AUTOSAR XML (schema 3.1.2)
package /Components/SWC_EOMGsl
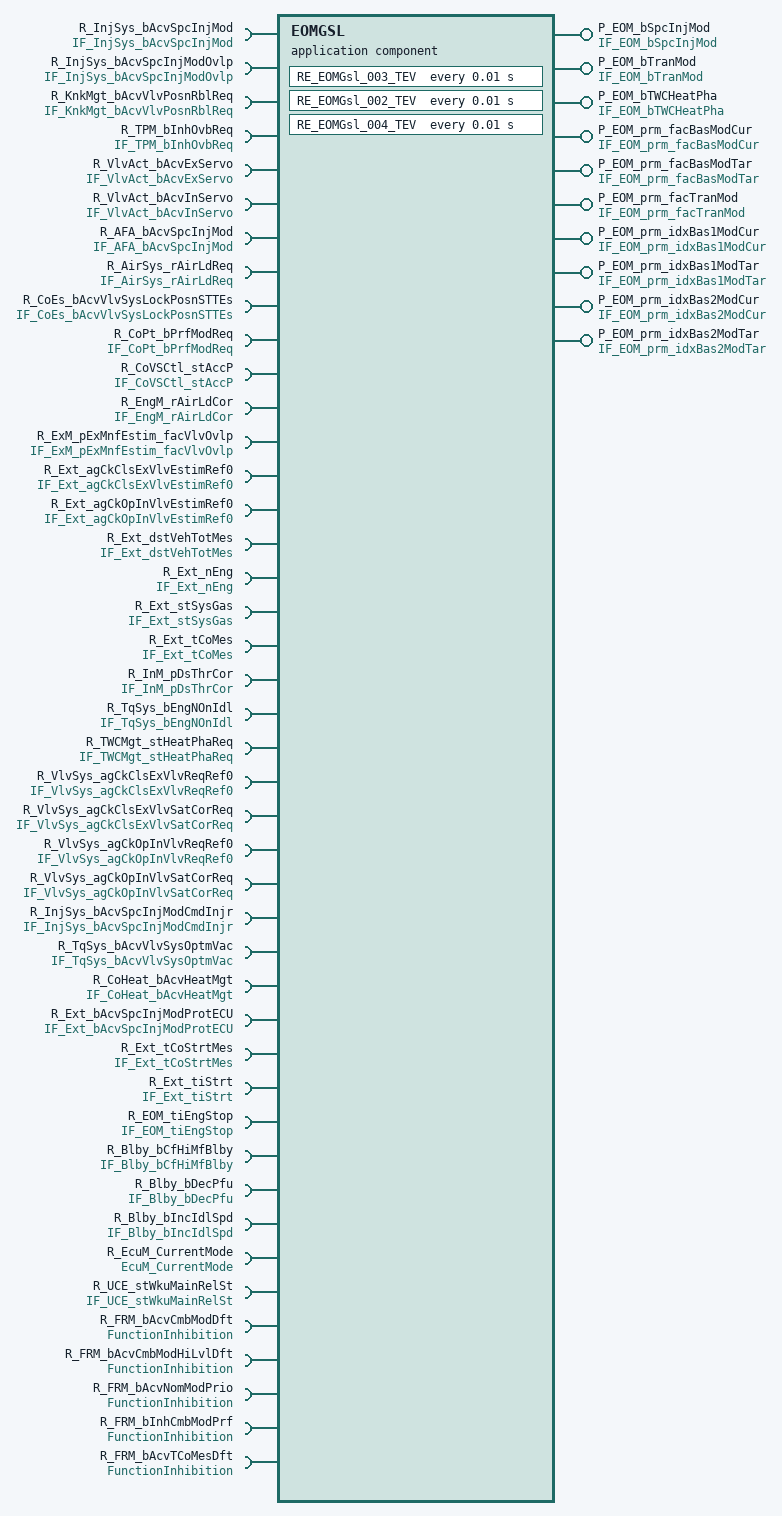
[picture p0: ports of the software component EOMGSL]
  application software component type EOMGSL
    43 x require port:
      R_InjSys_bAcvSpcInjMod: unqueued-receiver-com-spec{data-element=InjSys_bAcvSpcInjMod, init-value=ConstantValue, resync-time=0}, required-interface=IF_InjSys_bAcvSpcInjMod  # Receiver of interface IF_InjSys_bAcvSpcInjMod - Requirement Reference: [01552_10_03637-EOMGsl.I004(0)]
      R_InjSys_bAcvSpcInjModOvlp: unqueued-receiver-com-spec{data-element=InjSys_bAcvSpcInjModOvlp, init-value=ConstantValue1, resync-time=0}, required-interface=IF_InjSys_bAcvSpcInjModOvlp  # Receiver of interface IF_InjSys_bAcvSpcInjModOvlp - Requirement Reference: [01552_10_03637-EOMGsl.I005(0)]
      R_KnkMgt_bAcvVlvPosnRblReq: unqueued-receiver-com-spec{data-element=KnkMgt_bAcvVlvPosnRblReq, init-value=ConstantValue3, resync-time=0}, required-interface=IF_KnkMgt_bAcvVlvPosnRblReq  # Receiver of interface IF_KnkMgt_bAcvVlvPosnRblReq - Requirement Reference: [01552_10_03637-EOMGsl.I006(0)]
      R_TPM_bInhOvbReq: unqueued-receiver-com-spec{data-element=TPM_bInhOvbReq, init-value=ConstantValue5, resync-time=0}, required-interface=IF_TPM_bInhOvbReq  # Receiver of interface IF_TPM_bInhOvbReq - Requirement Reference: [01552_10_03637-EOMGsl.I007(0)]
      R_VlvAct_bAcvExServo: unqueued-receiver-com-spec{data-element=VlvAct_bAcvExServo, init-value=ConstantValue7, resync-time=0}, required-interface=IF_VlvAct_bAcvExServo  # Receiver of interface IF_VlvAct_bAcvExServo - Requirement Reference: [01552_10_03637-EOMGsl.I008(0)]
      R_VlvAct_bAcvInServo: unqueued-receiver-com-spec{data-element=VlvAct_bAcvInServo, init-value=ConstantValue9, resync-time=0}, required-interface=IF_VlvAct_bAcvInServo  # Receiver of interface IF_VlvAct_bAcvInServo - Requirement Reference: [01552_10_03637-EOMGsl.I009(1)]
      R_AFA_bAcvSpcInjMod: unqueued-receiver-com-spec{data-element=AFA_bAcvSpcInjMod, init-value=ConstantValue11, resync-time=0}, required-interface=IF_AFA_bAcvSpcInjMod  # Receiver of interface IF_AFA_bAcvSpcInjMod - Requirement Reference: [01552_10_03637-EOMGsl.I010(0)]
      R_AirSys_rAirLdReq: unqueued-receiver-com-spec{data-element=AirSys_rAirLdReq, init-value=ConstantValue13, resync-time=0}, required-interface=IF_AirSys_rAirLdReq  # Receiver of interface IF_AirSys_rAirLdReq - Requirement Reference: [01552_10_03637-EOMGsl.I011(1)]
      R_CoEs_bAcvVlvSysLockPosnSTTEs: unqueued-receiver-com-spec{data-element=CoEs_bAcvVlvSysLockPosnSTTEs, init-value=ConstantValue15, resync-time=0}, required-interface=IF_CoEs_bAcvVlvSysLockPosnSTTEs  # Receiver of interface IF_CoEs_bAcvVlvSysLockPosnSTTEs - Requirement Reference: [01552_10_03637-EOMGsl.I012(0)]
      R_CoPt_bPrfModReq: unqueued-receiver-com-spec{data-element=CoPt_bPrfModReq, init-value=ConstantValue17, resync-time=0}, required-interface=IF_CoPt_bPrfModReq  # Receiver of interface IF_CoPt_bPrfModReq - Requirement Reference: [01552_10_03637-EOMGsl.I013(1)]
      R_CoVSCtl_stAccP: unqueued-receiver-com-spec{data-element=CoVSCtl_stAccP, init-value=ConstantValue19, resync-time=0}, required-interface=IF_CoVSCtl_stAccP  # Receiver of interface IF_CoVSCtl_stAccP - Requirement Reference: [01552_10_03637-EOMGsl.I014(0)]
      R_EngM_rAirLdCor: unqueued-receiver-com-spec{data-element=EngM_rAirLdCor, init-value=ConstantValue21, resync-time=0}, required-interface=IF_EngM_rAirLdCor  # Receiver of interface IF_EngM_rAirLdCor - Requirement Reference: [01552_10_03637-EOMGsl.I015(1)]
      R_ExM_pExMnfEstim_facVlvOvlp: unqueued-receiver-com-spec{data-element=ExM_pExMnfEstim_facVlvOvlp, init-value=ConstantValue23, resync-time=0}, required-interface=IF_ExM_pExMnfEstim_facVlvOvlp  # Receiver of interface IF_ExM_pExMnfEstim_facVlvOvlp - Requirement Reference: [01552_10_03637-EOMGsl.I019(0)]
      R_Ext_agCkClsExVlvEstimRef0: unqueued-receiver-com-spec{data-element=Ext_agCkClsExVlvEstimRef0, init-value=ConstantValue25, resync-time=0}, required-interface=IF_Ext_agCkClsExVlvEstimRef0  # Receiver of interface IF_Ext_agCkClsExVlvEstimRef0 - Requirement Reference: [01552_10_03637-EOMGsl.I020(1)]
      R_Ext_agCkOpInVlvEstimRef0: unqueued-receiver-com-spec{data-element=Ext_agCkOpInVlvEstimRef0, init-value=ConstantValue27, resync-time=0}, required-interface=IF_Ext_agCkOpInVlvEstimRef0  # Receiver of interface IF_Ext_agCkOpInVlvEstimRef0 - Requirement Reference: [01552_10_03637-EOMGsl.I021(1)]
      R_Ext_dstVehTotMes: unqueued-receiver-com-spec{data-element=Ext_dstVehTotMes, init-value=ConstantValue29, resync-time=0}, required-interface=IF_Ext_dstVehTotMes  # Receiver of interface IF_Ext_dstVehTotMes - Requirement Reference: [01552_10_03637-EOMGsl.I022(0)]
      R_Ext_nEng: unqueued-receiver-com-spec{data-element=Ext_nEng, init-value=ConstantValue31, resync-time=0}, required-interface=IF_Ext_nEng  # Receiver of interface IF_Ext_nEng - Requirement Reference: [01552_10_03637-EOMGsl.I023(0)]
      R_Ext_stSysGas: unqueued-receiver-com-spec{data-element=Ext_stSysGas, init-value=ConstantValue33, resync-time=0}, required-interface=IF_Ext_stSysGas  # Receiver of interface IF_Ext_stSysGas - Requirement Reference: [01552_10_03637-EOMGsl.I024(1)]
      R_Ext_tCoMes: unqueued-receiver-com-spec{data-element=Ext_tCoMes, init-value=ConstantValue35, resync-time=0}, required-interface=IF_Ext_tCoMes  # Receiver of interface IF_Ext_tCoMes - Requirement Reference: [01552_10_03637-EOMGsl.I025(0)]
      R_InM_pDsThrCor: unqueued-receiver-com-spec{data-element=InM_pDsThrCor, init-value=ConstantValue37, resync-time=0}, required-interface=IF_InM_pDsThrCor  # Receiver of interface IF_InM_pDsThrCor - Requirement Reference: [01552_10_03637-EOMGsl.I026(0)]
      R_TqSys_bEngNOnIdl: unqueued-receiver-com-spec{data-element=TqSys_bEngNOnIdl, init-value=ConstantValue39, resync-time=0}, required-interface=IF_TqSys_bEngNOnIdl  # Receiver of interface IF_TqSys_bEngNOnIdl - Requirement Reference: [01552_10_03637-EOMGsl.I027(0)]
      R_TWCMgt_stHeatPhaReq: unqueued-receiver-com-spec{data-element=TWCMgt_stHeatPhaReq, init-value=ConstantValue41, resync-time=0}, required-interface=IF_TWCMgt_stHeatPhaReq  # Receiver of interface IF_TWCMgt_stHeatPhaReq - Requirement Reference: [01552_10_03637-EOMGsl.I028(0)]
      R_VlvSys_agCkClsExVlvReqRef0: unqueued-receiver-com-spec{data-element=VlvSys_agCkClsExVlvReqRef0, init-value=ConstantValue43, resync-time=0}, required-interface=IF_VlvSys_agCkClsExVlvReqRef0  # Receiver of interface IF_VlvSys_agCkClsExVlvReqRef0 - Requirement Reference: [01552_10_03637-EOMGsl.I029(2)]
      R_VlvSys_agCkClsExVlvSatCorReq: unqueued-receiver-com-spec{data-element=VlvSys_agCkClsExVlvSatCorReq, init-value=ConstantValue45, resync-time=0}, required-interface=IF_VlvSys_agCkClsExVlvSatCorReq  # Receiver of interface IF_VlvSys_agCkClsExVlvSatCorReq - Requirement Reference: [01552_10_03637-EOMGsl.I030(1)]
      R_VlvSys_agCkOpInVlvReqRef0: unqueued-receiver-com-spec{data-element=VlvSys_agCkOpInVlvReqRef0, init-value=ConstantValue47, resync-time=0}, required-interface=IF_VlvSys_agCkOpInVlvReqRef0  # Receiver of interface IF_VlvSys_agCkOpInVlvReqRef0 - Requirement Reference: [01552_10_03637-EOMGsl.I031(2)]
      R_VlvSys_agCkOpInVlvSatCorReq: unqueued-receiver-com-spec{data-element=VlvSys_agCkOpInVlvSatCorReq, init-value=ConstantValue49, resync-time=0}, required-interface=IF_VlvSys_agCkOpInVlvSatCorReq  # Receiver of interface IF_VlvSys_agCkOpInVlvSatCorReq - Requirement Reference: [01552_10_03637-EOMGsl.I032(1)]
      R_InjSys_bAcvSpcInjModCmdInjr: unqueued-receiver-com-spec{data-element=InjSys_bAcvSpcInjModCmdInjr, init-value=ConstantValue51, resync-time=0}, required-interface=IF_InjSys_bAcvSpcInjModCmdInjr  # Receiver of interface IF_InjSys_bAcvSpcInjModCmdInjr - Requirement Reference: [01552_10_03637-EOMGsl.I065(0)]
      R_TqSys_bAcvVlvSysOptmVac: unqueued-receiver-com-spec{data-element=TqSys_bAcvVlvSysOptmVac, init-value=ConstantValue53, resync-time=0}, required-interface=IF_TqSys_bAcvVlvSysOptmVac  # Receiver of interface IF_TqSys_bAcvVlvSysOptmVac - Requirement Reference: [01552_10_03637-EOMGsl.I088(0)]
      R_CoHeat_bAcvHeatMgt: unqueued-receiver-com-spec{data-element=CoHeat_bAcvHeatMgt, init-value=ConstantValue55, resync-time=0}, required-interface=IF_CoHeat_bAcvHeatMgt  # Receiver of interface IF_CoHeat_bAcvHeatMgt - Requirement Reference: [01552_10_03637-EOMGsl.I091(0)]
      R_Ext_bAcvSpcInjModProtECU: unqueued-receiver-com-spec{data-element=Ext_bAcvSpcInjModProtECU, init-value=ConstantValue57, resync-time=0}, required-interface=IF_Ext_bAcvSpcInjModProtECU  # Receiver of interface IF_Ext_bAcvSpcInjModProtECU - Requirement Reference: [01552_10_03637-EOMGsl.I092(0)]
      R_Ext_tCoStrtMes: unqueued-receiver-com-spec{data-element=Ext_tCoStrtMes, init-value=ConstantValue59, resync-time=0}, required-interface=IF_Ext_tCoStrtMes  # Receiver of interface IF_Ext_tCoStrtMes - Requirement Reference: [01552_10_03637-EOMGsl.I093(0)]
      R_Ext_tiStrt: unqueued-receiver-com-spec{data-element=Ext_tiStrt, init-value=ConstantValue61, resync-time=0}, required-interface=IF_Ext_tiStrt  # Receiver of interface IF_Ext_tiStrt - Requirement Reference: [01552_10_03637-EOMGsl-I094(0)]
      R_EOM_tiEngStop: unqueued-receiver-com-spec{data-element=EOM_tiEngStop, init-value=ConstantValue63, resync-time=0}, required-interface=IF_EOM_tiEngStop  # Receiver of interface IF_EOM_tiEngStop - Requirement Reference: [01552_10_03637-EOMGsl-I095(0)]
      R_Blby_bCfHiMfBlby: unqueued-receiver-com-spec{data-element=Blby_bCfHiMfBlby, init-value=ConstantValue65, resync-time=0}, required-interface=IF_Blby_bCfHiMfBlby  # Receiver of interface IF_Blby_bCfHiMfBlby - Requirement Reference: [01552_10_03637-EOMGsl-I096(0)]
      R_Blby_bDecPfu: unqueued-receiver-com-spec{data-element=Blby_bDecPfu, init-value=ConstantValue67, resync-time=0}, required-interface=IF_Blby_bDecPfu  # Receiver of interface IF_Blby_bDecPfu - Requirement Reference: [01552_10_03637-EOMGsl-I097(0)]
      R_Blby_bIncIdlSpd: unqueued-receiver-com-spec{data-element=Blby_bIncIdlSpd, init-value=ConstantValue69, resync-time=0}, required-interface=IF_Blby_bIncIdlSpd  # Receiver of interface IF_Blby_bIncIdlSpd - Requirement Reference: [01552_10_03637-EOMGsl-I098(0)]
      R_EcuM_CurrentMode: required-interface=EcuM_CurrentMode
      R_UCE_stWkuMainRelSt: required-interface=IF_UCE_stWkuMainRelSt
      R_FRM_bAcvCmbModDft: required-interface=FunctionInhibition  # 01552_10_03637-EOMGsl.I060(0)
      R_FRM_bAcvCmbModHiLvlDft: required-interface=FunctionInhibition  # 01552_10_03637-EOMGsl.I061(0)
      R_FRM_bAcvNomModPrio: required-interface=FunctionInhibition  # 01552_10_03637-EOMGsl.I062(0)
      R_FRM_bInhCmbModPrf: required-interface=FunctionInhibition  # 01552_10_03637-EOMGsl.I063(0)
      R_FRM_bAcvTCoMesDft: required-interface=FunctionInhibition  # 01552_10_03637-EOMGsl.I064(0)
    10 x provide port:
      P_EOM_bSpcInjMod: unqueued-sender-com-spec{data-element=EOM_bSpcInjMod, can-invalidate=false, init-value=ConstantValue71}, provided-interface=IF_EOM_bSpcInjMod
      P_EOM_bTranMod: unqueued-sender-com-spec{data-element=EOM_bTranMod, can-invalidate=false, init-value=ConstantValue73}, provided-interface=IF_EOM_bTranMod
      P_EOM_bTWCHeatPha: unqueued-sender-com-spec{data-element=EOM_bTWCHeatPha, can-invalidate=false, init-value=ConstantValue75}, provided-interface=IF_EOM_bTWCHeatPha
      P_EOM_prm_facBasModCur: unqueued-sender-com-spec{data-element=EOM_prm_facBasModCur, can-invalidate=false, init-value=EOM_prm_facBasModCur_Cst}, provided-interface=IF_EOM_prm_facBasModCur
      P_EOM_prm_facBasModTar: unqueued-sender-com-spec{data-element=EOM_prm_facBasModTar, can-invalidate=false, init-value=EOM_prm_facBasModTar_Cst}, provided-interface=IF_EOM_prm_facBasModTar
      P_EOM_prm_facTranMod: unqueued-sender-com-spec{data-element=EOM_prm_facTranMod, can-invalidate=false, init-value=EOM_prm_facTranMod_Cst}, provided-interface=IF_EOM_prm_facTranMod
      P_EOM_prm_idxBas1ModCur: unqueued-sender-com-spec{data-element=EOM_prm_idxBas1ModCur, can-invalidate=false, init-value=EOM_prm_idxBas1ModCur_Cst}, provided-interface=IF_EOM_prm_idxBas1ModCur
      P_EOM_prm_idxBas1ModTar: unqueued-sender-com-spec{data-element=EOM_prm_idxBas1ModTar, can-invalidate=false, init-value=EOM_prm_idxBas1ModTar_Cst}, provided-interface=IF_EOM_prm_idxBas1ModTar
      P_EOM_prm_idxBas2ModCur: unqueued-sender-com-spec{data-element=EOM_prm_idxBas2ModCur, can-invalidate=false, init-value=EOM_prm_idxBas2ModCur_Cst}, provided-interface=IF_EOM_prm_idxBas2ModCur
      P_EOM_prm_idxBas2ModTar: unqueued-sender-com-spec{data-element=EOM_prm_idxBas2ModTar, can-invalidate=false, init-value=EOM_prm_idxBas2ModTar_Cst}, provided-interface=IF_EOM_prm_idxBas2ModTar
  68 x constant specification:
    ConstantValue
      value:
        boolean literal ConstantValue: type=DT_InjSys_bAcvSpcInjMod, value=false
    ConstantValue1
      value:
        boolean literal ConstantValue1: type=DT_InjSys_bAcvSpcInjModOvlp, value=false
    ConstantValue11
      value:
        boolean literal ConstantValue11: type=DT_AFA_bAcvSpcInjMod, value=false
    ConstantValue13
      value:
        integer literal ConstantValue13: type=DT_AirSys_rAirLdReq, value=0
    ConstantValue15
      value:
        boolean literal ConstantValue15: type=DT_CoEs_bAcvVlvSysLockPosnSTTEs, value=false
    ConstantValue17
      value:
        boolean literal ConstantValue17: type=DT_CoPt_bPrfModReq, value=false
    ConstantValue19
      value:
        integer literal ConstantValue19: type=DT_CoVSCtl_stAccP, value=0
    ConstantValue21
      value:
        integer literal ConstantValue21: type=DT_EngM_rAirLdCor, value=0
    ConstantValue23
      value:
        integer literal ConstantValue23: type=DT_ExM_pExMnfEstim_facVlvOvlp, value=0
    ConstantValue25
      value:
        integer literal ConstantValue25: type=DT_Ext_agCkClsExVlvEstimRef0, value=-1024
    ConstantValue27
      value:
        integer literal ConstantValue27: type=DT_Ext_agCkOpInVlvEstimRef0, value=-1024
    ConstantValue29
      value:
        integer literal ConstantValue29: type=DT_Ext_dstVehTotMes, value=0
    ConstantValue3
      value:
        boolean literal ConstantValue3: type=DT_KnkMgt_bAcvVlvPosnRblReq, value=false
    ConstantValue31
      value:
        integer literal ConstantValue31: type=DT_Ext_nEng, value=0
    ConstantValue33
      value:
        integer literal ConstantValue33: type=DT_Ext_stSysGas, value=0
    ConstantValue35
      value:
        integer literal ConstantValue35: type=DT_Ext_tCoMes, value=20
    ConstantValue37
      value:
        integer literal ConstantValue37: type=DT_InM_pDsThrCor, value=0
    ConstantValue39
      value:
        boolean literal ConstantValue39: type=DT_TqSys_bEngNOnIdl, value=true
    ConstantValue41
      value:
        integer literal ConstantValue41: type=DT_TWCMgt_stHeatPhaReq, value=0
    ConstantValue43
      value:
        integer literal ConstantValue43: type=DT_VlvSys_agCkClsExVlvReqRef0, value=128
    ConstantValue45
      value:
        integer literal ConstantValue45: type=DT_VlvSys_agCkClsExVlvSatCorReq, value=-128
    ConstantValue47
      value:
        integer literal ConstantValue47: type=DT_VlvSys_agCkOpInVlvReqRef0, value=128
    ConstantValue49
      value:
        integer literal ConstantValue49: type=DT_VlvSys_agCkOpInVlvSatCorReq, value=-128
    ConstantValue5
      value:
        boolean literal ConstantValue5: type=DT_TPM_bInhOvbReq, value=false
    ConstantValue51
      value:
        boolean literal ConstantValue51: type=DT_InjSys_bAcvSpcInjModCmdInjr, value=false
    ConstantValue53
      value:
        boolean literal ConstantValue53: type=DT_TqSys_bAcvVlvSysOptmVac, value=false
    ConstantValue55
      value:
        boolean literal ConstantValue55: type=DT_CoHeat_bAcvHeatMgt, value=false
    ConstantValue57
      value:
        boolean literal ConstantValue57: type=DT_Ext_bAcvSpcInjModProtECU, value=false
    ConstantValue59
      value:
        integer literal ConstantValue59: type=DT_Ext_tCoStrtMes, value=-40
    ConstantValue61
      value:
        integer literal ConstantValue61: type=DT_Ext_tiStrt, value=0
    ConstantValue63
      value:
        integer literal ConstantValue63: type=DT_EOM_tiEngStop, value=864000
    ConstantValue65
      value:
        boolean literal ConstantValue65: type=DT_Blby_bCfHiMfBlby, value=false
    ConstantValue67
      value:
        boolean literal ConstantValue67: type=DT_Blby_bDecPfu, value=false
    ConstantValue69
      value:
        boolean literal ConstantValue69: type=DT_Blby_bIncIdlSpd, value=false
    ConstantValue7
      value:
        boolean literal ConstantValue7: type=DT_VlvAct_bAcvExServo, value=false
    ConstantValue71
      value:
        boolean literal ConstantValue71: type=DT_EOM_bSpcInjMod, value=false
    ConstantValue73
      value:
        boolean literal ConstantValue73: type=DT_EOM_bTranMod, value=false
    ConstantValue75
      value:
        boolean literal ConstantValue75: type=DT_EOM_bTWCHeatPha, value=false
    ConstantValue9
      value:
        boolean literal ConstantValue9: type=DT_VlvAct_bAcvInServo, value=false
    EOM_bDiTran_Cst
      value:
        boolean literal EOM_bDiTran_Cst: type=DT_EOM_bDiTran, value=false
    EOM_bEnaCmbModChg_Cst
      value:
        boolean literal EOM_bEnaCmbModChg_Cst: type=DT_EOM_bEnaCmbModChg, value=false
    EOM_bFdoutModReq_Cst
      value:
        boolean literal EOM_bFdoutModReq_Cst: type=DT_EOM_bFdoutModReq, value=false
    EOM_prm_facBasModCur_Cst
      value:
        array specification EOM_prm_facBasModCur_Cst: type=Array_16_UInt8
          16 x integer literal, all with type=DT_EOM_prm_facBasModCur, value=0:
            Element_{0..15}
    EOM_prm_facBasModTar_Cst
      value:
        array specification EOM_prm_facBasModTar_Cst: type=Array_16_UInt8_m1
          16 x integer literal, all with type=DT_EOM_prm_facBasModTar, value=0:
            Element_{0..15}
    EOM_prm_facTranMod_Cst
      value:
        array specification EOM_prm_facTranMod_Cst: type=Array_16_UInt8_m2
          16 x integer literal, all with type=DT_EOM_prm_facTranMod, value=0:
            Element_{0..15}
    EOM_prm_facTranModNotSync_01_Cst
      value:
        integer literal EOM_prm_facTranModNotSync_01_Cst: type=DT_EOM_prm_facTranModNotSync_01, value=0
    EOM_prm_facTranModNotSync_02_Cst
      value:
        integer literal EOM_prm_facTranModNotSync_02_Cst: type=DT_EOM_prm_facTranModNotSync_02, value=0
    EOM_prm_facTranModNotSync_03_Cst
      value:
        integer literal EOM_prm_facTranModNotSync_03_Cst: type=DT_EOM_prm_facTranModNotSync_03, value=0
    EOM_prm_facTranModNotSync_04_Cst
      value:
        integer literal EOM_prm_facTranModNotSync_04_Cst: type=DT_EOM_prm_facTranModNotSync_04, value=0
    EOM_prm_facTranModNotSync_05_Cst
      value:
        integer literal EOM_prm_facTranModNotSync_05_Cst: type=DT_EOM_prm_facTranModNotSync_05, value=0
    EOM_prm_facTranModNotSync_06_Cst
      value:
        integer literal EOM_prm_facTranModNotSync_06_Cst: type=DT_EOM_prm_facTranModNotSync_06, value=0
    EOM_prm_facTranModNotSync_07_Cst
      value:
        integer literal EOM_prm_facTranModNotSync_07_Cst: type=DT_EOM_prm_facTranModNotSync_07, value=0
    EOM_prm_facTranModNotSync_08_Cst
      value:
        integer literal EOM_prm_facTranModNotSync_08_Cst: type=DT_EOM_prm_facTranModNotSync_08, value=0
    EOM_prm_facTranModNotSync_09_Cst
      value:
        integer literal EOM_prm_facTranModNotSync_09_Cst: type=DT_EOM_prm_facTranModNotSync_09, value=0
    EOM_prm_facTranModNotSync_10_Cst
      value:
        integer literal EOM_prm_facTranModNotSync_10_Cst: type=DT_EOM_prm_facTranModNotSync_10, value=0
    EOM_prm_facTranModNotSync_11_Cst
      value:
        integer literal EOM_prm_facTranModNotSync_11_Cst: type=DT_EOM_prm_facTranModNotSync_11, value=0
    EOM_prm_facTranModNotSync_12_Cst
      value:
        integer literal EOM_prm_facTranModNotSync_12_Cst: type=DT_EOM_prm_facTranModNotSync_12, value=0
    EOM_prm_facTranModNotSync_13_Cst
      value:
        integer literal EOM_prm_facTranModNotSync_13_Cst: type=DT_EOM_prm_facTranModNotSync_13, value=0
    EOM_prm_facTranModNotSync_14_Cst
      value:
        integer literal EOM_prm_facTranModNotSync_14_Cst: type=DT_EOM_prm_facTranModNotSync_14, value=0
    EOM_prm_facTranModNotSync_15_Cst
      value:
        integer literal EOM_prm_facTranModNotSync_15_Cst: type=DT_EOM_prm_facTranModNotSync_15, value=0
    EOM_prm_facTranModNotSync_16_Cst
      value:
        integer literal EOM_prm_facTranModNotSync_16_Cst: type=DT_EOM_prm_facTranModNotSync_16, value=0
    EOM_prm_idxBas1ModCur_Cst
      value:
        array specification EOM_prm_idxBas1ModCur_Cst: type=Array_16_UInt8_m3
          16 x integer literal, all with type=DT_EOM_prm_idxBas1ModCur, value=1:
            Element_{0..15}
    EOM_prm_idxBas1ModTar_Cst
      value:
        array specification EOM_prm_idxBas1ModTar_Cst: type=Array_16_UInt8_m4
          16 x integer literal, all with type=DT_EOM_prm_idxBas1ModTar, value=1:
            Element_{0..15}
    EOM_prm_idxBas2ModCur_Cst
      value:
        array specification EOM_prm_idxBas2ModCur_Cst: type=Array_16_UInt8_m5
          16 x integer literal, all with type=DT_EOM_prm_idxBas2ModCur, value=1:
            Element_{0..15}
    EOM_prm_idxBas2ModTar_Cst
      value:
        array specification EOM_prm_idxBas2ModTar_Cst: type=Array_16_UInt8_m6
          16 x integer literal, all with type=DT_EOM_prm_idxBas2ModTar, value=1:
            Element_{0..15}
    EOM_stCmbModCur_Cst
      value:
        integer literal EOM_stCmbModCur_Cst: type=DT_EOM_stCmbModCur, value=0
    EOM_stCmbModReq_Cst
      value:
        integer literal EOM_stCmbModReq_Cst: type=DT_EOM_stCmbModReq, value=0
    EOM_stCmbModTar_Cst
      value:
        integer literal EOM_stCmbModTar_Cst: type=DT_EOM_stCmbModTar, value=0
  internal behavior IB_EOMGsl: component=EOMGSL
    timing event EV_EOMGsl_003_TEV: mode-dependency=dependent-on-mode=[R_UCE_stWkuMainRelSt.RCD_stWkuMainRelSt.Invalid, R_UCE_stWkuMainRelSt.RCD_stWkuMainRelSt.PostMainWakeUp, R_UCE_stWkuMainRelSt.RCD_stWkuMainRelSt.PreMainWakeUp], start-on-event=RE_EOMGsl_003_TEV, period=0.01
    mode switch event EV_EOMGsl_001_MSE: start-on-event=RE_EOMGsl_001_MSE, activation=ENTRY, mode=R_EcuM_CurrentMode.currentMode.RUN
    timing event EV_EOMGsl_002_TEV: mode-dependency=dependent-on-mode=[R_UCE_stWkuMainRelSt.RCD_stWkuMainRelSt.Invalid, R_UCE_stWkuMainRelSt.RCD_stWkuMainRelSt.PostMainWakeUp, R_UCE_stWkuMainRelSt.RCD_stWkuMainRelSt.PreMainWakeUp], start-on-event=RE_EOMGsl_002_TEV, period=0.01
    timing event EV_EOMGsl_004_TEV: mode-dependency=dependent-on-mode=[R_UCE_stWkuMainRelSt.RCD_stWkuMainRelSt.Invalid, R_UCE_stWkuMainRelSt.RCD_stWkuMainRelSt.PostMainWakeUp, R_UCE_stWkuMainRelSt.RCD_stWkuMainRelSt.PreMainWakeUp], start-on-event=RE_EOMGsl_004_TEV, period=0.01
    22 x inter runnable variable, all with sw-calibration-access=READ-WRITE, communication-approach=EXPLICIT:
      EOM_prm_facTranModNotSync_04: type=DT_EOM_prm_facTranModNotSync_04, init-value=EOM_prm_facTranModNotSync_04_Cst  # [01552_10_03637-EOMGsl.I072(1)] - Vecteur des facteurs d'interpolation transition de modes non synchronisés
      EOM_prm_facTranModNotSync_07: type=DT_EOM_prm_facTranModNotSync_07, init-value=EOM_prm_facTranModNotSync_07_Cst  # [01552_10_03637-EOMGsl.I075(1)] - Vecteur des facteurs d'interpolation transition de modes non synchronisés
      EOM_stCmbModTar: type=DT_EOM_stCmbModTar, init-value=EOM_stCmbModTar_Cst  # [01552_10_03637-EOMGsl.I086(1)] - Numéro du mode consigne
      EOM_prm_facTranModNotSync_09: type=DT_EOM_prm_facTranModNotSync_09, init-value=EOM_prm_facTranModNotSync_09_Cst  # [01552_10_03637-EOMGsl.I077(1)] - Vecteur des facteurs d'interpolation transition de modes non synchronisés
      EOM_prm_facTranModNotSync_02: type=DT_EOM_prm_facTranModNotSync_02, init-value=EOM_prm_facTranModNotSync_02_Cst  # [01552_10_03637-EOMGsl.I070(1)] - Vecteur des facteurs d'interpolation transition de modes non synchronisés
      EOM_stCmbModReq: type=DT_EOM_stCmbModReq, init-value=EOM_stCmbModReq_Cst  # [01552_10_03637-EOMGsl.I068(1)] - Numéro du mode cible
      EOM_prm_facTranModNotSync_01: type=DT_EOM_prm_facTranModNotSync_01, init-value=EOM_prm_facTranModNotSync_01_Cst  # [01552_10_03637-EOMGsl.I069(1)] - Vecteur des facteurs d'interpolation transition de modes non synchronisés
      EOM_prm_facTranModNotSync_16: type=DT_EOM_prm_facTranModNotSync_16, init-value=EOM_prm_facTranModNotSync_16_Cst  # [01552_10_03637-EOMGsl.I084(1)] - Vecteur des facteurs d'interpolation transition de modes non synchronisés
      EOM_prm_facTranModNotSync_05: type=DT_EOM_prm_facTranModNotSync_05, init-value=EOM_prm_facTranModNotSync_05_Cst  # [01552_10_03637-EOMGsl.I073(1)] - Vecteur des facteurs d'interpolation transition de modes non synchronisés
      EOM_bDiTran: type=DT_EOM_bDiTran, init-value=EOM_bDiTran_Cst  # [01552_10_03637-EOMGsl.I066(1)] - Flag d'annulation de transition lente (0=transition lente; 1=transition directe)
      EOM_prm_facTranModNotSync_06: type=DT_EOM_prm_facTranModNotSync_06, init-value=EOM_prm_facTranModNotSync_06_Cst  # [01552_10_03637-EOMGsl.I074(1)] - Vecteur des facteurs d'interpolation transition de modes non synchronisés
      EOM_prm_facTranModNotSync_11: type=DT_EOM_prm_facTranModNotSync_11, init-value=EOM_prm_facTranModNotSync_11_Cst  # [01552_10_03637-EOMGsl.I079(1)] - Vecteur des facteurs d'interpolation transition de modes non synchronisés
      EOM_prm_facTranModNotSync_13: type=DT_EOM_prm_facTranModNotSync_13, init-value=EOM_prm_facTranModNotSync_13_Cst  # [01552_10_03637-EOMGsl.I081(1)] - Vecteur des facteurs d'interpolation transition de modes non synchronisés
      EOM_bFdoutModReq: type=DT_EOM_bFdoutModReq, init-value=EOM_bFdoutModReq_Cst  # [01552_10_03637-EOMGsl.I067(1)] - Booléen d'état encrassé
      EOM_prm_facTranModNotSync_10: type=DT_EOM_prm_facTranModNotSync_10, init-value=EOM_prm_facTranModNotSync_10_Cst  # [01552_10_03637-EOMGsl.I078(1)] - Vecteur des facteurs d'interpolation transition de modes non synchronisés
      EOM_prm_facTranModNotSync_08: type=DT_EOM_prm_facTranModNotSync_08, init-value=EOM_prm_facTranModNotSync_08_Cst  # [01552_10_03637-EOMGsl.I076(1)] - Vecteur des facteurs d'interpolation transition de modes non synchronisés
      EOM_bEnaCmbModChg: type=DT_EOM_bEnaCmbModChg, init-value=EOM_bEnaCmbModChg_Cst  # [01552_10_03637-EOMGsl.I087(2)] - Flag d'autorisation de changement de mode (1 quand autorisation)
      EOM_prm_facTranModNotSync_14: type=DT_EOM_prm_facTranModNotSync_14, init-value=EOM_prm_facTranModNotSync_14_Cst  # [01552_10_03637-EOMGsl.I082(1)] - Vecteur des facteurs d'interpolation transition de modes non synchronisés
      EOM_prm_facTranModNotSync_03: type=DT_EOM_prm_facTranModNotSync_03, init-value=EOM_prm_facTranModNotSync_03_Cst  # [01552_10_03637-EOMGsl.I071(1)] - Vecteur des facteurs d'interpolation transition de modes non synchronisés
      EOM_prm_facTranModNotSync_12: type=DT_EOM_prm_facTranModNotSync_12, init-value=EOM_prm_facTranModNotSync_12_Cst  # [01552_10_03637-EOMGsl.I080(1)] - Vecteur des facteurs d'interpolation transition de modes non synchronisés
      EOM_stCmbModCur: type=DT_EOM_stCmbModCur, init-value=EOM_stCmbModCur_Cst  # [01552_10_03637-EOMGsl.I091(0)] - Numéro du mode courant
      EOM_prm_facTranModNotSync_15: type=DT_EOM_prm_facTranModNotSync_15, init-value=EOM_prm_facTranModNotSync_15_Cst  # [01552_10_03637-EOMGsl.I083(1)] - Vecteur des facteurs d'interpolation transition de modes non synchronisés
    4 x runnable:
      RE_EOMGsl_004_TEV: read-variable=[EOM_stCmbModReq, EOM_bFdoutModReq, EOM_bDiTran], written-variable=[EOM_stCmbModCur, EOM_stCmbModTar, EOM_prm_facTranModNotSync_12, EOM_bEnaCmbModChg, EOM_prm_facTranModNotSync_04, EOM_prm_facTranModNotSync_07, EOM_prm_facTranModNotSync_01, EOM_prm_facTranModNotSync_08, EOM_prm_facTranModNotSync_09, EOM_prm_facTranModNotSync_14, EOM_prm_facTranModNotSync_03, EOM_prm_facTranModNotSync_10, EOM_prm_facTranModNotSync_06, EOM_prm_facTranModNotSync_11, EOM_prm_facTranModNotSync_13, EOM_prm_facTranModNotSync_16, EOM_prm_facTranModNotSync_02, EOM_prm_facTranModNotSync_05, EOM_prm_facTranModNotSync_15]  # 01552_10_03637-EOMGsl.A004(2)
        data send point ds_EOM_bTWCHeatPha: data-element=P_EOM_bTWCHeatPha.EOM_bTWCHeatPha
        data send point ds_EOM_bTranMod: data-element=P_EOM_bTranMod.EOM_bTranMod
        data send point ds_EOM_bSpcInjMod: data-element=P_EOM_bSpcInjMod.EOM_bSpcInjMod
      RE_EOMGsl_001_MSE: written-variable=[EOM_prm_facTranModNotSync_03, EOM_prm_facTranModNotSync_06, EOM_stCmbModTar, EOM_prm_facTranModNotSync_02, EOM_stCmbModCur, EOM_prm_facTranModNotSync_16, EOM_prm_facTranModNotSync_15, EOM_stCmbModReq, EOM_prm_facTranModNotSync_05, EOM_bFdoutModReq, EOM_bDiTran, EOM_prm_facTranModNotSync_04, EOM_prm_facTranModNotSync_01, EOM_prm_facTranModNotSync_11, EOM_bEnaCmbModChg, EOM_prm_facTranModNotSync_10, EOM_prm_facTranModNotSync_09, EOM_prm_facTranModNotSync_08, EOM_prm_facTranModNotSync_14, EOM_prm_facTranModNotSync_13, EOM_prm_facTranModNotSync_12, EOM_prm_facTranModNotSync_07]  # 01552_10_03637-EOMGsl.A001(3)
        10 x data send point:
          ds_EOM_bTWCHeatPha: data-element=P_EOM_bTWCHeatPha.EOM_bTWCHeatPha
          ds_EOM_prm_idxBas2ModTar: data-element=P_EOM_prm_idxBas2ModTar.EOM_prm_idxBas2ModTar
          ds_EOM_prm_facBasModCur: data-element=P_EOM_prm_facBasModCur.EOM_prm_facBasModCur
          ds_EOM_bSpcInjMod: data-element=P_EOM_bSpcInjMod.EOM_bSpcInjMod
          ds_EOM_prm_facTranMod: data-element=P_EOM_prm_facTranMod.EOM_prm_facTranMod
          ds_EOM_prm_facBasModTar: data-element=P_EOM_prm_facBasModTar.EOM_prm_facBasModTar
          ds_EOM_prm_idxBas2ModCur: data-element=P_EOM_prm_idxBas2ModCur.EOM_prm_idxBas2ModCur
          ds_EOM_prm_idxBas1ModCur: data-element=P_EOM_prm_idxBas1ModCur.EOM_prm_idxBas1ModCur
          ds_EOM_prm_idxBas1ModTar: data-element=P_EOM_prm_idxBas1ModTar.EOM_prm_idxBas1ModTar
          ds_EOM_bTranMod: data-element=P_EOM_bTranMod.EOM_bTranMod
      RE_EOMGsl_002_TEV: read-variable=EOM_bEnaCmbModChg, written-variable=[EOM_bDiTran, EOM_bFdoutModReq, EOM_stCmbModReq]  # 01552_10_03637-EOMGsl.A002(3)
        33 x data receive point:
          dr_VlvSys_agCkOpInVlvSatCorReq: data-element=R_VlvSys_agCkOpInVlvSatCorReq.VlvSys_agCkOpInVlvSatCorReq
          dr_Ext_bAcvSpcInjModProtECU: data-element=R_Ext_bAcvSpcInjModProtECU.Ext_bAcvSpcInjModProtECU
          dr_TWCMgt_stHeatPhaReq: data-element=R_TWCMgt_stHeatPhaReq.TWCMgt_stHeatPhaReq
          dr_Ext_agCkClsExVlvEstimRef0: data-element=R_Ext_agCkClsExVlvEstimRef0.Ext_agCkClsExVlvEstimRef0
          dr_Ext_stSysGas: data-element=R_Ext_stSysGas.Ext_stSysGas
          dr_InjSys_bAcvSpcInjModOvlp: data-element=R_InjSys_bAcvSpcInjModOvlp.InjSys_bAcvSpcInjModOvlp
          dr_Blby_bDecPfu: data-element=R_Blby_bDecPfu.Blby_bDecPfu
          dr_Ext_tCoMes: data-element=R_Ext_tCoMes.Ext_tCoMes
          dr_Blby_bIncIdlSpd: data-element=R_Blby_bIncIdlSpd.Blby_bIncIdlSpd
          dr_TPM_bInhOvbReq: data-element=R_TPM_bInhOvbReq.TPM_bInhOvbReq
          dr_Ext_nEng: data-element=R_Ext_nEng.Ext_nEng
          dr_VlvAct_bAcvExServo: data-element=R_VlvAct_bAcvExServo.VlvAct_bAcvExServo
          dr_TqSys_bAcvVlvSysOptmVac: data-element=R_TqSys_bAcvVlvSysOptmVac.TqSys_bAcvVlvSysOptmVac
          dr_AirSys_rAirLdReq: data-element=R_AirSys_rAirLdReq.AirSys_rAirLdReq
          dr_VlvSys_agCkClsExVlvSatCorReq: data-element=R_VlvSys_agCkClsExVlvSatCorReq.VlvSys_agCkClsExVlvSatCorReq
          dr_InM_pDsThrCor: data-element=R_InM_pDsThrCor.InM_pDsThrCor
          dr_TqSys_bEngNOnIdl: data-element=R_TqSys_bEngNOnIdl.TqSys_bEngNOnIdl
          dr_InjSys_bAcvSpcInjMod: data-element=R_InjSys_bAcvSpcInjMod.InjSys_bAcvSpcInjMod
          dr_AFA_bAcvSpcInjMod: data-element=R_AFA_bAcvSpcInjMod.AFA_bAcvSpcInjMod
          dr_Ext_dstVehTotMes: data-element=R_Ext_dstVehTotMes.Ext_dstVehTotMes
          dr_ExM_pExMnfEstim_facVlvOvlp: data-element=R_ExM_pExMnfEstim_facVlvOvlp.ExM_pExMnfEstim_facVlvOvlp
          dr_CoVSCtl_stAccP: data-element=R_CoVSCtl_stAccP.CoVSCtl_stAccP
          dr_CoPt_bPrfModReq: data-element=R_CoPt_bPrfModReq.CoPt_bPrfModReq
          dr_VlvSys_agCkOpInVlvReqRef0: data-element=R_VlvSys_agCkOpInVlvReqRef0.VlvSys_agCkOpInVlvReqRef0
          dr_KnkMgt_bAcvVlvPosnRblReq: data-element=R_KnkMgt_bAcvVlvPosnRblReq.KnkMgt_bAcvVlvPosnRblReq
          dr_EngM_rAirLdCor: data-element=R_EngM_rAirLdCor.EngM_rAirLdCor
          dr_CoHeat_bAcvHeatMgt: data-element=R_CoHeat_bAcvHeatMgt.CoHeat_bAcvHeatMgt
          dr_VlvSys_agCkClsExVlvReqRef0: data-element=R_VlvSys_agCkClsExVlvReqRef0.VlvSys_agCkClsExVlvReqRef0
          dr_InjSys_bAcvSpcInjModCmdInjr: data-element=R_InjSys_bAcvSpcInjModCmdInjr.InjSys_bAcvSpcInjModCmdInjr
          dr_Blby_bCfHiMfBlby: data-element=R_Blby_bCfHiMfBlby.Blby_bCfHiMfBlby
          dr_VlvAct_bAcvInServo: data-element=R_VlvAct_bAcvInServo.VlvAct_bAcvInServo
          dr_Ext_agCkOpInVlvEstimRef0: data-element=R_Ext_agCkOpInVlvEstimRef0.Ext_agCkOpInVlvEstimRef0
          dr_CoEs_bAcvVlvSysLockPosnSTTEs: data-element=R_CoEs_bAcvVlvSysLockPosnSTTEs.CoEs_bAcvVlvSysLockPosnSTTEs
        5 x sync call:
          SC_FRM_bAcvCmbModHiLvlDft: operation=R_FRM_bAcvCmbModHiLvlDft.GetFunctionPermission
          SC_FRM_bInhCmbModPrf: operation=R_FRM_bInhCmbModPrf.GetFunctionPermission
          SC_FRM_bAcvTCoMesDft: operation=R_FRM_bAcvTCoMesDft.GetFunctionPermission
          SC_FRM_bAcvNomModPrio: operation=R_FRM_bAcvNomModPrio.GetFunctionPermission
          SC_FRM_bAcvCmbModDft: operation=R_FRM_bAcvCmbModDft.GetFunctionPermission
      RE_EOMGsl_003_TEV: read-variable=[EOM_stCmbModTar, EOM_prm_facTranModNotSync_03, EOM_prm_facTranModNotSync_11, EOM_prm_facTranModNotSync_13, EOM_prm_facTranModNotSync_10, EOM_prm_facTranModNotSync_12, EOM_prm_facTranModNotSync_08, EOM_prm_facTranModNotSync_09, EOM_stCmbModCur, EOM_prm_facTranModNotSync_02, EOM_prm_facTranModNotSync_04, EOM_prm_facTranModNotSync_06, EOM_prm_facTranModNotSync_15, EOM_prm_facTranModNotSync_14, EOM_prm_facTranModNotSync_05, EOM_prm_facTranModNotSync_01, EOM_prm_facTranModNotSync_07, EOM_prm_facTranModNotSync_16]  # 01552_10_03637-EOMGsl.A003(4)
        4 x data receive point:
          dr_Ext_tCoMes: data-element=R_Ext_tCoMes.Ext_tCoMes
          dr_EOM_tiEngStop: data-element=R_EOM_tiEngStop.EOM_tiEngStop
          dr_Ext_tCoStrtMes: data-element=R_Ext_tCoStrtMes.Ext_tCoStrtMes
          dr_Ext_tiStrt: data-element=R_Ext_tiStrt.Ext_tiStrt
        7 x data send point:
          ds_EOM_prm_idxBas1ModCur: data-element=P_EOM_prm_idxBas1ModCur.EOM_prm_idxBas1ModCur
          ds_EOM_prm_facBasModTar: data-element=P_EOM_prm_facBasModTar.EOM_prm_facBasModTar
          ds_EOM_prm_facTranMod: data-element=P_EOM_prm_facTranMod.EOM_prm_facTranMod
          ds_EOM_prm_idxBas2ModCur: data-element=P_EOM_prm_idxBas2ModCur.EOM_prm_idxBas2ModCur
          ds_EOM_prm_idxBas1ModTar: data-element=P_EOM_prm_idxBas1ModTar.EOM_prm_idxBas1ModTar
          ds_EOM_prm_idxBas2ModTar: data-element=P_EOM_prm_idxBas2ModTar.EOM_prm_idxBas2ModTar
          ds_EOM_prm_facBasModCur: data-element=P_EOM_prm_facBasModCur.EOM_prm_facBasModCur
        sync call SC_FRM_bAcvTCoMesDft: operation=R_FRM_bAcvTCoMesDft.GetFunctionPermission
  swc implementation Imp_EOMGsl: programming-language=C, behavior=IB_EOMGsl
    code-descriptors:
      code CodeDescriptor: type=SRC
        17 x xfile:
          EOMGsl_nvm_h: url=EOMGsl_nvm.h
          EOMGsl_002_TEV_fct_c: url=EOMGsl_002_TEV_fct.c
          EOMGsl_004_calibrations_h: url=EOMGsl_004_calibrations.h
          EOMGsl_002_calibrations_h: url=EOMGsl_002_calibrations.h
          EOMGsl_nvm_c: url=EOMGsl_nvm.c
          EOMGsl_h: url=EOMGsl.h
          EOMGsl_004_TEV_fct_h: url=EOMGsl_004_TEV_fct.h
          EOMGsl_MemMap_h: url=EOMGsl_MemMap.h
          EOMGsl_003_calibrations_c: url=EOMGsl_003_calibrations.c
          EOMGsl_002_calibrations_c: url=EOMGsl_002_calibrations.c
          EOMGsl_004_calibrations_c: url=EOMGsl_004_calibrations.c
          EOMGsl_c: url=EOMGsl.c
          EOMGsl_003_calibrations_h: url=EOMGsl_003_calibrations.h
          EOMGsl_003_TEV_fct_h: url=EOMGsl_003_TEV_fct.h
          EOMGsl_002_TEV_fct_h: url=EOMGsl_002_TEV_fct.h
          EOMGsl_003_TEV_fct_c: url=EOMGsl_003_TEV_fct.c
          EOMGsl_004_TEV_fct_c: url=EOMGsl_004_TEV_fct.c
package /Components/SWC_EOMGsl/EOMGsl_IRVDatatypes
  boolean type DT_EOM_bDiTran: base-type=boolean
  boolean type DT_EOM_bEnaCmbModChg: base-type=boolean
  boolean type DT_EOM_bFdoutModReq: base-type=boolean
  19 x integer type, all with base-type=uint8, lower-limit=0, upper-limit=255:
    DT_EOM_prm_facTranModNotSync_{01..16}
    DT_EOM_stCmbModCur
    DT_EOM_stCmbModReq
    DT_EOM_stCmbModTar
